VERSION ""

NS_ :

BS_:

BU_:

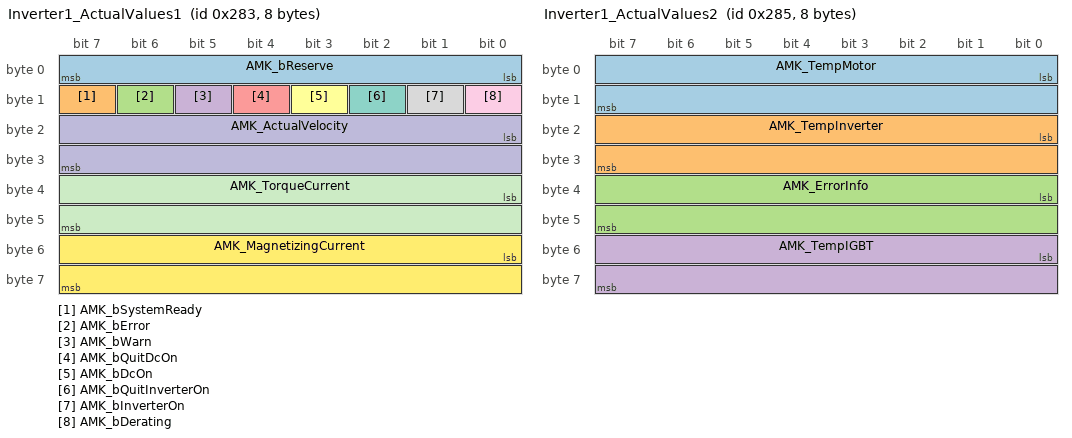
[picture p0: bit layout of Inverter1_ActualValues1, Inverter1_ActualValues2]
BO_ 643 Inverter1_ActualValues1: 8 Vector__XXX
 SG_ AMK_bReserve : 0|8@1+ (1,0) [0|0] "" Vector__XXX
 SG_ AMK_bSystemReady : 15|1@1+ (1,0) [0|0] "" Vector__XXX
 SG_ AMK_bError : 14|1@1+ (1,0) [0|0] "" Vector__XXX
 SG_ AMK_bWarn : 13|1@1+ (1,0) [0|0] "" Vector__XXX
 SG_ AMK_bQuitDcOn : 12|1@1+ (1,0) [0|0] "" Vector__XXX
 SG_ AMK_bDcOn : 11|1@1+ (1,0) [0|0] "" Vector__XXX
 SG_ AMK_bQuitInverterOn : 10|1@1+ (1,0) [0|0] "" Vector__XXX
 SG_ AMK_bInverterOn : 9|1@1+ (1,0) [0|0] "" Vector__XXX
 SG_ AMK_bDerating : 8|1@1+ (1,0) [0|0] "" Vector__XXX
 SG_ AMK_ActualVelocity : 16|16@1- (1,0) [0|0] "" Vector__XXX
 SG_ AMK_TorqueCurrent : 32|16@1- (1,0) [0|0] "" Vector__XXX
 SG_ AMK_MagnetizingCurrent : 48|16@1- (1,0) [0|0] "" Vector__XXX

BO_ 645 Inverter1_ActualValues2: 8 Vector__XXX
 SG_ AMK_TempMotor : 0|16@1- (1,0) [0|0] "" Vector__XXX
 SG_ AMK_TempInverter : 16|16@1- (1,0) [0|0] "" Vector__XXX
 SG_ AMK_ErrorInfo : 32|16@1+ (1,0) [0|0] "" Vector__XXX
 SG_ AMK_TempIGBT : 48|16@1- (1,0) [0|0] "" Vector__XXX

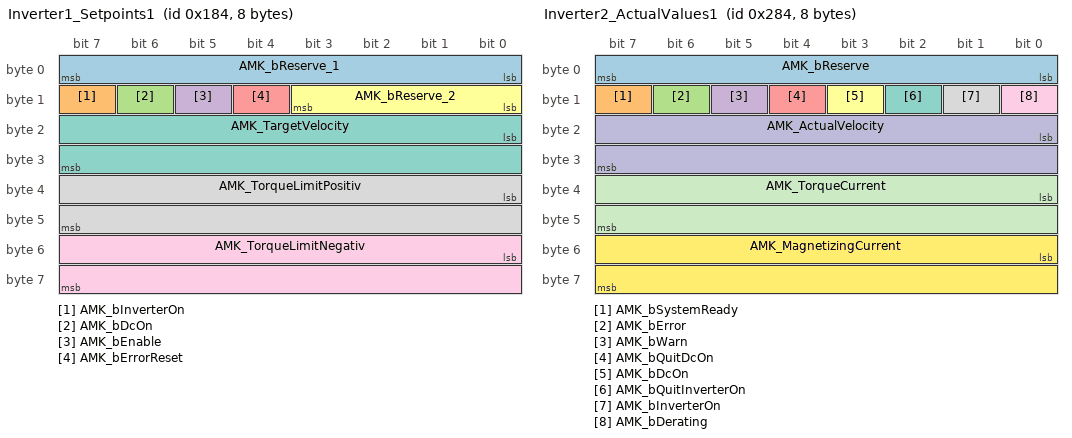
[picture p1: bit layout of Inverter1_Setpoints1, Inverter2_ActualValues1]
BO_ 388 Inverter1_Setpoints1: 8 Vector__XXX
 SG_ AMK_bReserve_1 : 0|8@1+ (1,0) [0|0] "" Vector__XXX
 SG_ AMK_bInverterOn : 15|1@1+ (1,0) [0|0] "" Vector__XXX
 SG_ AMK_bDcOn : 14|1@1+ (1,0) [0|0] "" Vector__XXX
 SG_ AMK_bEnable : 13|1@1+ (1,0) [0|0] "" Vector__XXX
 SG_ AMK_bErrorReset : 12|1@1+ (1,0) [0|0] "" Vector__XXX
 SG_ AMK_bReserve_2 : 8|4@1+ (1,0) [0|0] "" Vector__XXX
 SG_ AMK_TargetVelocity : 16|16@1- (1,0) [0|0] "" Vector__XXX
 SG_ AMK_TorqueLimitPositiv : 32|16@1- (1,0) [0|0] "" Vector__XXX
 SG_ AMK_TorqueLimitNegativ : 48|16@1- (1,0) [0|0] "" Vector__XXX

BO_ 644 Inverter2_ActualValues1: 8 Vector__XXX
 SG_ AMK_bReserve : 0|8@1+ (1,0) [0|0] "" Vector__XXX
 SG_ AMK_bSystemReady : 15|1@1+ (1,0) [0|0] "" Vector__XXX
 SG_ AMK_bError : 14|1@1+ (1,0) [0|0] "" Vector__XXX
 SG_ AMK_bWarn : 13|1@1+ (1,0) [0|0] "" Vector__XXX
 SG_ AMK_bQuitDcOn : 12|1@1+ (1,0) [0|0] "" Vector__XXX
 SG_ AMK_bDcOn : 11|1@1+ (1,0) [0|0] "" Vector__XXX
 SG_ AMK_bQuitInverterOn : 10|1@1+ (1,0) [0|0] "" Vector__XXX
 SG_ AMK_bInverterOn : 9|1@1+ (1,0) [0|0] "" Vector__XXX
 SG_ AMK_bDerating : 8|1@1+ (1,0) [0|0] "" Vector__XXX
 SG_ AMK_ActualVelocity : 16|16@1- (1,0) [0|0] "" Vector__XXX
 SG_ AMK_TorqueCurrent : 32|16@1- (1,0) [0|0] "" Vector__XXX
 SG_ AMK_MagnetizingCurrent : 48|16@1- (1,0) [0|0] "" Vector__XXX

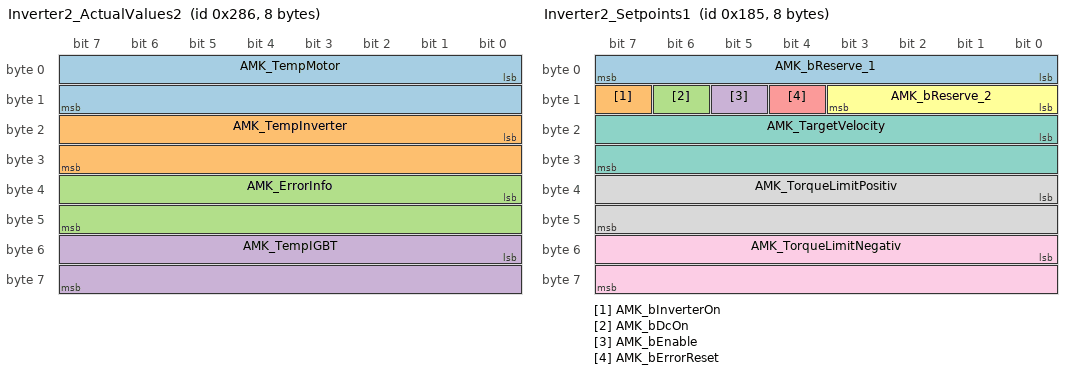
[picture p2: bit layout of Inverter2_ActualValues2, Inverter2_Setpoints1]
BO_ 646 Inverter2_ActualValues2: 8 Vector__XXX
 SG_ AMK_TempMotor : 0|16@1- (1,0) [0|0] "" Vector__XXX
 SG_ AMK_TempInverter : 16|16@1- (1,0) [0|0] "" Vector__XXX
 SG_ AMK_ErrorInfo : 32|16@1+ (1,0) [0|0] "" Vector__XXX
 SG_ AMK_TempIGBT : 48|16@1- (1,0) [0|0] "" Vector__XXX

BO_ 389 Inverter2_Setpoints1: 8 Vector__XXX
 SG_ AMK_bReserve_1 : 0|8@1+ (1,0) [0|0] "" Vector__XXX
 SG_ AMK_bInverterOn : 15|1@1+ (1,0) [0|0] "" Vector__XXX
 SG_ AMK_bDcOn : 14|1@1+ (1,0) [0|0] "" Vector__XXX
 SG_ AMK_bEnable : 13|1@1+ (1,0) [0|0] "" Vector__XXX
 SG_ AMK_bErrorReset : 12|1@1+ (1,0) [0|0] "" Vector__XXX
 SG_ AMK_bReserve_2 : 8|4@1+ (1,0) [0|0] "" Vector__XXX
 SG_ AMK_TargetVelocity : 16|16@1- (1,0) [0|0] "" Vector__XXX
 SG_ AMK_TorqueLimitPositiv : 32|16@1- (1,0) [0|0] "" Vector__XXX
 SG_ AMK_TorqueLimitNegativ : 48|16@1- (1,0) [0|0] "" Vector__XXX

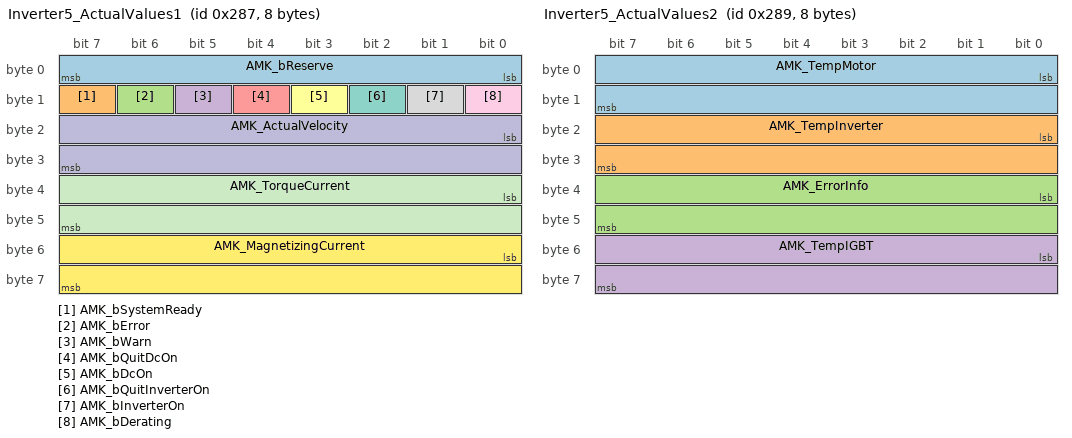
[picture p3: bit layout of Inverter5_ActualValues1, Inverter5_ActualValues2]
BO_ 647 Inverter5_ActualValues1: 8 Vector__XXX
 SG_ AMK_bReserve : 0|8@1+ (1,0) [0|0] "" Vector__XXX
 SG_ AMK_bSystemReady : 15|1@1+ (1,0) [0|0] "" Vector__XXX
 SG_ AMK_bError : 14|1@1+ (1,0) [0|0] "" Vector__XXX
 SG_ AMK_bWarn : 13|1@1+ (1,0) [0|0] "" Vector__XXX
 SG_ AMK_bQuitDcOn : 12|1@1+ (1,0) [0|0] "" Vector__XXX
 SG_ AMK_bDcOn : 11|1@1+ (1,0) [0|0] "" Vector__XXX
 SG_ AMK_bQuitInverterOn : 10|1@1+ (1,0) [0|0] "" Vector__XXX
 SG_ AMK_bInverterOn : 9|1@1+ (1,0) [0|0] "" Vector__XXX
 SG_ AMK_bDerating : 8|1@1+ (1,0) [0|0] "" Vector__XXX
 SG_ AMK_ActualVelocity : 16|16@1- (1,0) [0|0] "" Vector__XXX
 SG_ AMK_TorqueCurrent : 32|16@1- (1,0) [0|0] "" Vector__XXX
 SG_ AMK_MagnetizingCurrent : 48|16@1- (1,0) [0|0] "" Vector__XXX

BO_ 649 Inverter5_ActualValues2: 8 Vector__XXX
 SG_ AMK_TempMotor : 0|16@1- (1,0) [0|0] "" Vector__XXX
 SG_ AMK_TempInverter : 16|16@1- (1,0) [0|0] "" Vector__XXX
 SG_ AMK_ErrorInfo : 32|16@1+ (1,0) [0|0] "" Vector__XXX
 SG_ AMK_TempIGBT : 48|16@1- (1,0) [0|0] "" Vector__XXX

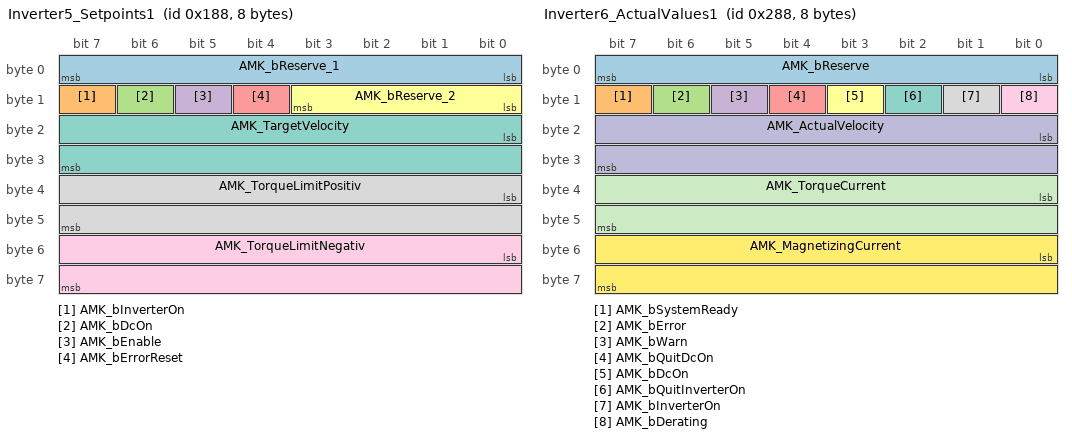
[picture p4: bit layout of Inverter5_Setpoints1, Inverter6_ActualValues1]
BO_ 392 Inverter5_Setpoints1: 8 Vector__XXX
 SG_ AMK_bReserve_1 : 0|8@1+ (1,0) [0|0] "" Vector__XXX
 SG_ AMK_bInverterOn : 15|1@1+ (1,0) [0|0] "" Vector__XXX
 SG_ AMK_bDcOn : 14|1@1+ (1,0) [0|0] "" Vector__XXX
 SG_ AMK_bEnable : 13|1@1+ (1,0) [0|0] "" Vector__XXX
 SG_ AMK_bErrorReset : 12|1@1+ (1,0) [0|0] "" Vector__XXX
 SG_ AMK_bReserve_2 : 8|4@1+ (1,0) [0|0] "" Vector__XXX
 SG_ AMK_TargetVelocity : 16|16@1- (1,0) [0|0] "" Vector__XXX
 SG_ AMK_TorqueLimitPositiv : 32|16@1- (1,0) [0|0] "" Vector__XXX
 SG_ AMK_TorqueLimitNegativ : 48|16@1- (1,0) [0|0] "" Vector__XXX

BO_ 648 Inverter6_ActualValues1: 8 Vector__XXX
 SG_ AMK_bReserve : 0|8@1+ (1,0) [0|0] "" Vector__XXX
 SG_ AMK_bSystemReady : 15|1@1+ (1,0) [0|0] "" Vector__XXX
 SG_ AMK_bError : 14|1@1+ (1,0) [0|0] "" Vector__XXX
 SG_ AMK_bWarn : 13|1@1+ (1,0) [0|0] "" Vector__XXX
 SG_ AMK_bQuitDcOn : 12|1@1+ (1,0) [0|0] "" Vector__XXX
 SG_ AMK_bDcOn : 11|1@1+ (1,0) [0|0] "" Vector__XXX
 SG_ AMK_bQuitInverterOn : 10|1@1+ (1,0) [0|0] "" Vector__XXX
 SG_ AMK_bInverterOn : 9|1@1+ (1,0) [0|0] "" Vector__XXX
 SG_ AMK_bDerating : 8|1@1+ (1,0) [0|0] "" Vector__XXX
 SG_ AMK_ActualVelocity : 16|16@1- (1,0) [0|0] "" Vector__XXX
 SG_ AMK_TorqueCurrent : 32|16@1- (1,0) [0|0] "" Vector__XXX
 SG_ AMK_MagnetizingCurrent : 48|16@1- (1,0) [0|0] "" Vector__XXX

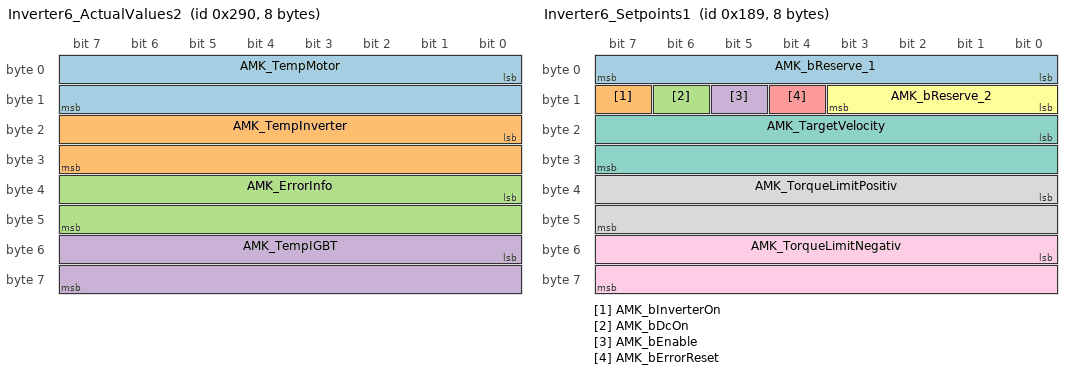
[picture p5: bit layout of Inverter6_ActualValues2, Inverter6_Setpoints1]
BO_ 656 Inverter6_ActualValues2: 8 Vector__XXX
 SG_ AMK_TempMotor : 0|16@1- (1,0) [0|0] "" Vector__XXX
 SG_ AMK_TempInverter : 16|16@1- (1,0) [0|0] "" Vector__XXX
 SG_ AMK_ErrorInfo : 32|16@1+ (1,0) [0|0] "" Vector__XXX
 SG_ AMK_TempIGBT : 48|16@1- (1,0) [0|0] "" Vector__XXX

BO_ 393 Inverter6_Setpoints1: 8 Vector__XXX
 SG_ AMK_bReserve_1 : 0|8@1+ (1,0) [0|0] "" Vector__XXX
 SG_ AMK_bInverterOn : 15|1@1+ (1,0) [0|0] "" Vector__XXX
 SG_ AMK_bDcOn : 14|1@1+ (1,0) [0|0] "" Vector__XXX
 SG_ AMK_bEnable : 13|1@1+ (1,0) [0|0] "" Vector__XXX
 SG_ AMK_bErrorReset : 12|1@1+ (1,0) [0|0] "" Vector__XXX
 SG_ AMK_bReserve_2 : 8|4@1+ (1,0) [0|0] "" Vector__XXX
 SG_ AMK_TargetVelocity : 16|16@1- (1,0) [0|0] "" Vector__XXX
 SG_ AMK_TorqueLimitPositiv : 32|16@1- (1,0) [0|0] "" Vector__XXX
 SG_ AMK_TorqueLimitNegativ : 48|16@1- (1,0) [0|0] "" Vector__XXX

BA_DEF_  "BusType" STRING ;
BA_DEF_DEF_  "BusType" "CAN";
